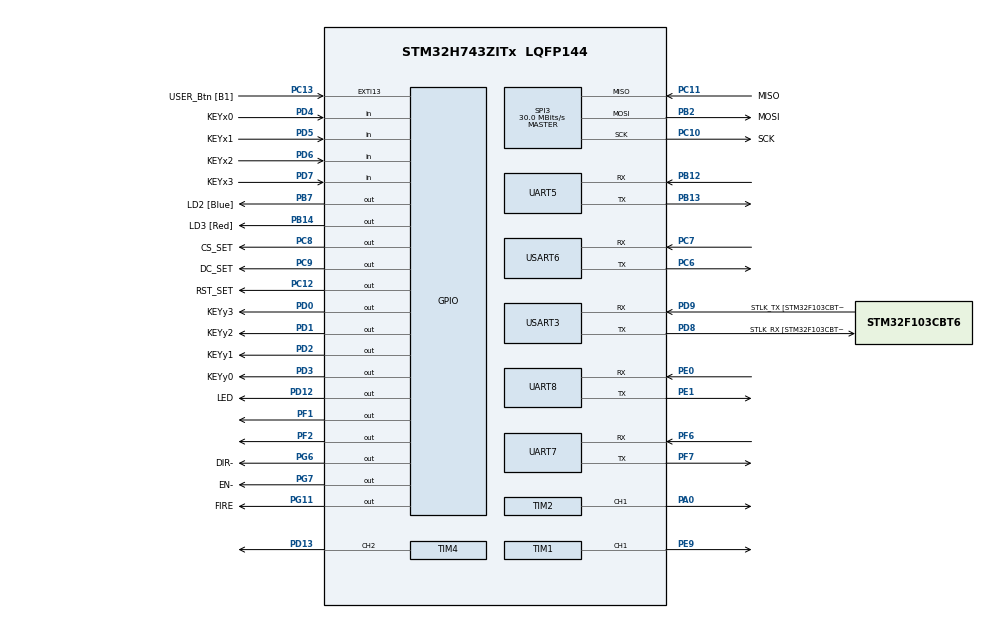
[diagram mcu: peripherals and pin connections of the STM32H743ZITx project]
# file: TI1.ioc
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Mcu.Family=STM32H7
Mcu.Name=STM32H743ZITx
Mcu.Package=LQFP144
NVIC.PriorityGroup=NVIC_PRIORITYGROUP_4
NVIC.TIM2_IRQn=true\:0\:0\:false\:false\:true\:true\:true
NVIC.UART5_IRQn=true\:1\:0\:true\:false\:true\:true\:true
NVIC.UART7_IRQn=true\:2\:0\:true\:false\:true\:true\:true
NVIC.USART3_IRQn=true\:3\:0\:true\:false\:true\:true\:true
PA0.Signal=S_TIM2_CH1
PB12.Mode=Asynchronous
PB12.Signal=UART5_RX
PB13.Mode=Asynchronous
PB13.Signal=UART5_TX
PB14.GPIO_Label=LD3 [Red]
PB14.Signal=GPIO_Output
PB2.GPIO_Label=MOSI
PB2.GPIO_Speed=GPIO_SPEED_FREQ_VERY_HIGH
PB2.Mode=Full_Duplex_Master
PB2.Signal=SPI3_MOSI
PB7.GPIO_Label=LD2 [Blue]
PB7.Signal=GPIO_Output
PC10.GPIO_Label=SCK
PC10.GPIO_Speed=GPIO_SPEED_FREQ_VERY_HIGH
PC10.Mode=Full_Duplex_Master
PC10.Signal=SPI3_SCK
PC11.GPIO_Label=MISO
PC11.GPIO_Speed=GPIO_SPEED_FREQ_VERY_HIGH
PC11.Mode=Full_Duplex_Master
PC11.Signal=SPI3_MISO
PC12.GPIO_Label=RST_SET
PC12.GPIO_Speed=GPIO_SPEED_FREQ_VERY_HIGH
PC12.Signal=GPIO_Output
PC13.GPIO_Label=USER_Btn [B1]
PC13.Signal=GPXTI13
PC14-OSC32_IN\ (OSC32_IN).Mode=LSE-External-Oscillator
PC14-OSC32_IN\ (OSC32_IN).Signal=RCC_OSC32_IN
PC15-OSC32_OUT\ (OSC32_OUT).Mode=LSE-External-Oscillator
PC15-OSC32_OUT\ (OSC32_OUT).Signal=RCC_OSC32_OUT
PC6.Mode=Asynchronous
PC6.Signal=USART6_TX
PC7.Mode=Asynchronous
PC7.Signal=USART6_RX
PC8.GPIO_Label=CS_SET
PC8.GPIO_Speed=GPIO_SPEED_FREQ_VERY_HIGH
PC8.Signal=GPIO_Output
PC9.GPIO_Label=DC_SET
PC9.Signal=GPIO_Output
PD0.GPIO_Label=KEYy3
PD0.GPIO_ModeDefaultOutputPP=GPIO_MODE_OUTPUT_PP
PD0.Signal=GPIO_Output
PD1.GPIO_Label=KEYy2
PD1.GPIO_ModeDefaultOutputPP=GPIO_MODE_OUTPUT_PP
PD1.Signal=GPIO_Output
PD12.GPIO_Label=LED
PD12.PinState=GPIO_PIN_SET
PD12.Signal=GPIO_Output
PD13.Signal=S_TIM4_CH2
PD2.GPIO_Label=KEYy1
PD2.GPIO_ModeDefaultOutputPP=GPIO_MODE_OUTPUT_PP
PD2.Signal=GPIO_Output
PD3.GPIO_Label=KEYy0
PD3.GPIO_ModeDefaultOutputPP=GPIO_MODE_OUTPUT_PP
PD3.Signal=GPIO_Output
PD4.GPIO_Label=KEYx0
PD4.GPIO_PuPd=GPIO_PULLUP
PD4.Signal=GPIO_Input
PD5.GPIO_Label=KEYx1
PD5.GPIO_PuPd=GPIO_PULLUP
PD5.Signal=GPIO_Input
PD6.GPIO_Label=KEYx2
PD6.GPIO_PuPd=GPIO_PULLUP
PD6.Signal=GPIO_Input
PD7.GPIO_Label=KEYx3
PD7.GPIO_PuPd=GPIO_PULLUP
PD7.Signal=GPIO_Input
PD8.GPIO_Label=STLK_RX [STM32F103CBT6_PA3]
PD8.Mode=Asynchronous
PD8.Signal=USART3_TX
PD9.GPIO_Label=STLK_TX [STM32F103CBT6_PA2]
PD9.Mode=Asynchronous
PD9.Signal=USART3_RX
PE0.Mode=Asynchronous
PE0.Signal=UART8_RX
PE1.Mode=Asynchronous
PE1.Signal=UART8_TX
PE9.Signal=S_TIM1_CH1
PF1.GPIO_Speed=GPIO_SPEED_FREQ_VERY_HIGH
PF1.PinState=GPIO_PIN_SET
PF1.Signal=GPIO_Output
PF2.GPIO_Speed=GPIO_SPEED_FREQ_VERY_HIGH
PF2.Signal=GPIO_Output
PF6.Mode=Asynchronous
PF6.Signal=UART7_RX
PF7.Mode=Asynchronous
PF7.Signal=UART7_TX
PG11.GPIO_Label=FIRE
PG11.PinState=GPIO_PIN_SET
PG11.Signal=GPIO_Output
PG6.GPIO_Label=DIR-
PG6.GPIO_Speed=GPIO_SPEED_FREQ_VERY_HIGH
PG6.PinState=GPIO_PIN_SET
PG6.Signal=GPIO_Output
PG7.GPIO_Label=EN-
PG7.GPIO_Speed=GPIO_SPEED_FREQ_VERY_HIGH
PG7.Signal=GPIO_Output
PH0-OSC_IN\ (PH0).GPIO_Label=MCO
PH0-OSC_IN\ (PH0).Mode=HSE-External-Clock-Source
PH0-OSC_IN\ (PH0).Signal=RCC_OSC_IN
PH1-OSC_OUT\ (PH1).Mode=HSE-External-Clock-Source
PH1-OSC_OUT\ (PH1).Signal=RCC_OSC_OUT
ProjectManager.HeapSize=0x200
ProjectManager.StackSize=0x400
ProjectManager.TargetToolchain=MDK-ARM V5
RCC.48MHZClocksFreq_Value=24000000
RCC.ADCFreq_Value=16125000
RCC.AHBFreq_Value=216000000
RCC.APB1CLKDivider=RCC_HCLK_DIV4
RCC.APB1Freq_Value=120000000
RCC.APB1TimFreq_Value=108000000
RCC.APB2CLKDivider=RCC_HCLK_DIV2
RCC.APB2Freq_Value=120000000
RCC.APB2TimFreq_Value=216000000
RCC.APB3Freq_Value=120000000
RCC.APB4Freq_Value=120000000
RCC.CortexFreq_Value=480000000
RCC.D1PPRE=RCC_APB3_DIV2
RCC.D2PPRE1=RCC_APB1_DIV2
RCC.D2PPRE2=RCC_APB2_DIV2
RCC.D3PPRE=RCC_APB4_DIV2
RCC.DIVM1=1
RCC.DIVN1=120
RCC.DIVQ1=4
RCC.HCLKFreq_Value=240000000
RCC.HPRE=RCC_HCLK_DIV2
RCC.HSE_VALUE=8000000
RCC.HSI_VALUE=64000000
RCC.PLLFRACN=0
RCC.PLLM=25
RCC.PLLMUL=RCC_PLL_MUL9
RCC.PLLN=432
RCC.PLLQ=9
RCC.PLLSourceVirtual=RCC_PLLSOURCE_HSE
RCC.PRESCALERUSB=RCC_USBCLKSOURCE_PLL_DIV1_5
RCC.PWR_Regulator_Voltage_Scale=PWR_REGULATOR_VOLTAGE_SCALE0
RCC.SYSCLKFreq_VALUE=480000000
RCC.SYSCLKSource=RCC_SYSCLKSOURCE_PLLCLK
RCC.SYSCLKSourceVirtual=RCC_SYSCLKSOURCE_PLLCLK
RCC.USBFreq_Value=240000000
RCC.VCOOutputFreq_Value=432000000
SH.S_TIM1_CH1.0=TIM1_CH1,PWM Generation1 CH1
SH.S_TIM2_CH1.0=TIM2_CH1,PWM Generation1 CH1
SH.S_TIM4_CH2.0=TIM4_CH2,PWM Generation2 CH2
SPI3.BaudRatePrescaler=SPI_BAUDRATEPRESCALER_8
SPI3.CLKPhase=SPI_PHASE_2EDGE
SPI3.CLKPolarity=SPI_POLARITY_HIGH
SPI3.CalculateBaudRate=30.0 MBits/s
SPI3.DataSize=SPI_DATASIZE_8BIT
SPI3.Direction=SPI_DIRECTION_2LINES
SPI3.Mode=SPI_MODE_MASTER
SPI3.NSSPMode=SPI_NSS_PULSE_DISABLE
SPI3.VirtualType=VM_MASTER
TIM1.Channel-PWM\ Generation1\ CH1=TIM_CHANNEL_1
TIM1.Period=39999
TIM1.Prescaler=3
TIM2.Channel-PWM\ Generation1\ CH1=TIM_CHANNEL_1
TIM2.Period=999
TIM2.Prescaler=239
TIM4.Channel-PWM\ Generation2\ CH2=TIM_CHANNEL_2
TIM4.Period=20000
TIM4.Prescaler=239
TIM4.Pulse-PWM\ Generation2\ CH2=1800
TIM5.Period=65536
TIM5.Prescaler=239
UART5.SwapParam=UART_ADVFEATURE_SWAP_DISABLE
UART7.DMADisableonRxErrorParam=UART_ADVFEATURE_DMA_DISABLEONRXERROR
UART7.OverrunDisableParam=UART_ADVFEATURE_OVERRUN_DISABLE
USART3.VirtualMode-Asynchronous=VM_ASYNC
USART6.VirtualMode-Asynchronous=VM_ASYNC
VP_TIM1_VS_ClockSourceINT.Mode=Internal
VP_TIM1_VS_ClockSourceITR.Mode=TriggerSource_ITR0
VP_TIM2_VS_ClockSourceINT.Mode=Internal
VP_TIM4_VS_ClockSourceINT.Mode=Internal
VP_TIM4_VS_ClockSourceITR.Mode=TriggerSource_ITR0
VP_TIM5_VS_ClockSourceINT.Mode=Internal
board=NUCLEO-H743ZI

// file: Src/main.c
/* USER CODE BEGIN Header */
/**
  ******************************************************************************
  * @file           : main.c
  * @brief          : Main program body
  ******************************************************************************
  * @attention
  *
  * <h2><center>&copy; Copyright (c) 2019 STMicroelectronics.
  * All rights reserved.</center></h2>
  *
  * This software component is licensed by ST under BSD 3-Clause license,
  * the "License"; You may not use this file except in compliance with the
  * License. You may obtain a copy of the License at:
  *                        opensource.org/licenses/BSD-3-Clause
  *
  ******************************************************************************
  */
/* USER CODE END Header */

#include "main.h"
#include "spi.h"
#include "tim.h"
#include "usart.h"
#include "gpio.h"

/* USER CODE BEGIN Includes */
#include "gui.h"
#include "User_main.h"
/* USER CODE END Includes */

void SystemClock_Config(void);

int main(void)
{

  /* MCU Configuration--------------------------------------------------------*/

  /* Reset of all peripherals, Initializes the Flash interface and the Systick. */
  HAL_Init();

  /* Configure the system clock */
  SystemClock_Config();

  /* Initialize all configured peripherals */
  MX_GPIO_Init();
  MX_USART3_UART_Init();
  MX_SPI3_Init();
  MX_TIM4_Init();
  MX_TIM1_Init();
  MX_UART5_Init();
  MX_TIM2_Init();
  MX_UART8_Init();
  MX_USART6_UART_Init();
  MX_UART7_Init();
  MX_TIM5_Init();
  /* USER CODE BEGIN 2 */
	Lcd_Init();
	Lcd_Clear(WHITE);
  /* USER CODE END 2 */

  /* Infinite loop */
  /* USER CODE BEGIN WHILE */
  while (1)
  {
		//Gui_DrawLine(0,0,100,100,RED);
		Usermain();
    /* USER CODE END WHILE */

  }
}

void SystemClock_Config(void)
{
  RCC_OscInitTypeDef RCC_OscInitStruct = {0};
  RCC_ClkInitTypeDef RCC_ClkInitStruct = {0};
  RCC_PeriphCLKInitTypeDef PeriphClkInitStruct = {0};

  /** Supply configuration update enable
  */
  HAL_PWREx_ConfigSupply(PWR_LDO_SUPPLY);
  /** Configure the main internal regulator output voltage
  */
  __HAL_PWR_VOLTAGESCALING_CONFIG(PWR_REGULATOR_VOLTAGE_SCALE0);

  while(!__HAL_PWR_GET_FLAG(PWR_FLAG_VOSRDY)) {}
  /** Initializes the CPU, AHB and APB busses clocks
  */
  RCC_OscInitStruct.OscillatorType = RCC_OSCILLATORTYPE_HSE;
  RCC_OscInitStruct.HSEState = RCC_HSE_BYPASS;
  RCC_OscInitStruct.PLL.PLLState = RCC_PLL_ON;
  RCC_OscInitStruct.PLL.PLLSource = RCC_PLLSOURCE_HSE;
  RCC_OscInitStruct.PLL.PLLM = 1;
  RCC_OscInitStruct.PLL.PLLN = 120;
  RCC_OscInitStruct.PLL.PLLP = 2;
  RCC_OscInitStruct.PLL.PLLQ = 4;
  RCC_OscInitStruct.PLL.PLLR = 2;
  RCC_OscInitStruct.PLL.PLLRGE = RCC_PLL1VCIRANGE_3;
  RCC_OscInitStruct.PLL.PLLVCOSEL = RCC_PLL1VCOWIDE;
  RCC_OscInitStruct.PLL.PLLFRACN = 0;
  if (HAL_RCC_OscConfig(&RCC_OscInitStruct) != HAL_OK)
  {
    Error_Handler();
  }
  /** Initializes the CPU, AHB and APB busses clocks
  */
  RCC_ClkInitStruct.ClockType = RCC_CLOCKTYPE_HCLK|RCC_CLOCKTYPE_SYSCLK
                              |RCC_CLOCKTYPE_PCLK1|RCC_CLOCKTYPE_PCLK2
                              |RCC_CLOCKTYPE_D3PCLK1|RCC_CLOCKTYPE_D1PCLK1;
  RCC_ClkInitStruct.SYSCLKSource = RCC_SYSCLKSOURCE_PLLCLK;
  RCC_ClkInitStruct.SYSCLKDivider = RCC_SYSCLK_DIV1;
  RCC_ClkInitStruct.AHBCLKDivider = RCC_HCLK_DIV2;
  RCC_ClkInitStruct.APB3CLKDivider = RCC_APB3_DIV2;
  RCC_ClkInitStruct.APB1CLKDivider = RCC_APB1_DIV2;
  RCC_ClkInitStruct.APB2CLKDivider = RCC_APB2_DIV2;
  RCC_ClkInitStruct.APB4CLKDivider = RCC_APB4_DIV2;

  if (HAL_RCC_ClockConfig(&RCC_ClkInitStruct, FLASH_LATENCY_4) != HAL_OK)
  {
    Error_Handler();
  }
  PeriphClkInitStruct.PeriphClockSelection = RCC_PERIPHCLK_USART3|RCC_PERIPHCLK_UART7
                              |RCC_PERIPHCLK_USART6|RCC_PERIPHCLK_UART8
                              |RCC_PERIPHCLK_UART5|RCC_PERIPHCLK_SPI3;
  PeriphClkInitStruct.Spi123ClockSelection = RCC_SPI123CLKSOURCE_PLL;
  PeriphClkInitStruct.Usart234578ClockSelection = RCC_USART234578CLKSOURCE_D2PCLK1;
  PeriphClkInitStruct.Usart16ClockSelection = RCC_USART16CLKSOURCE_D2PCLK2;
  if (HAL_RCCEx_PeriphCLKConfig(&PeriphClkInitStruct) != HAL_OK)
  {
    Error_Handler();
  }
}

void Error_Handler(void)
{
}

/************************ (C) COPYRIGHT STMicroelectronics *****END OF FILE****/
